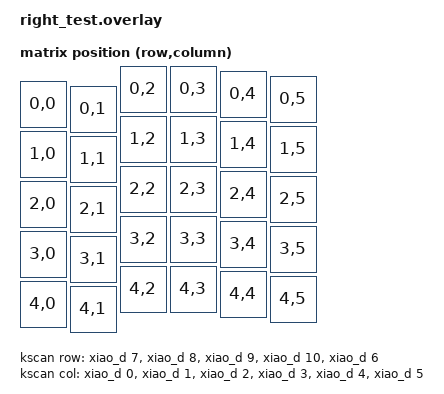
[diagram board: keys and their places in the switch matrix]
// This file was generated from a template. Edit it to match your keyboard.
// See https://zmk.dev/docs/development/hardware-integration/new-shield for more
// instructions.

#include <dt-bindings/zmk/matrix_transform.h>

#include "right_test-layouts.dtsi"

/ {
    chosen {
        zmk,physical-layout = &physical_layout0;
    };

    kscan: kscan {
        // If the hardware does not use a switch matrix, change this to the
        // appropriate driver and update the properties below to match.
        // See https://zmk.dev/docs/config/kscan for supported key scan drivers.
        compatible = "zmk,kscan-gpio-matrix";
        // Set this to "col2row" or "row2col" to match the hardware. If using
        // "row2col", change the col-gpios to (GPIO_ACTIVE_HIGH | GPIO_PULL_DOWN)
        // and the row-gpios to GPIO_ACTIVE_HIGH.
        diode-direction = "col2row";
        wakeup-source;

        // Replace these comments with the GPIO pins in the matrix.
        // See https://zmk.dev/docs/development/hardware-integration/new-shield#shield-overlays
        col-gpios
            = <&xiao_d 0 GPIO_ACTIVE_HIGH>
            , <&xiao_d 1 GPIO_ACTIVE_HIGH>
            , <&xiao_d 2 GPIO_ACTIVE_HIGH>
            , <&xiao_d 3 GPIO_ACTIVE_HIGH>
            , <&xiao_d 4 GPIO_ACTIVE_HIGH>
            , <&xiao_d 5 GPIO_ACTIVE_HIGH>
            ;

        row-gpios
            = <&xiao_d 7 (GPIO_ACTIVE_HIGH | GPIO_PULL_DOWN)>
            , <&xiao_d 8 (GPIO_ACTIVE_HIGH | GPIO_PULL_DOWN)>
            , <&xiao_d 9 (GPIO_ACTIVE_HIGH | GPIO_PULL_DOWN)>
            , <&xiao_d 10 (GPIO_ACTIVE_HIGH | GPIO_PULL_DOWN)>
            , <&xiao_d 6 (GPIO_ACTIVE_HIGH | GPIO_PULL_DOWN)>
            ;
    };

    default_transform: default_transform {
        // See https://zmk.dev/docs/development/hardware-integration/new-shield#matrix-transform
        // for how to configure this
        compatible = "zmk,matrix-transform";
        columns = <6>;
        rows = <5>;

        map = <
            RC(0, 0) RC(0, 1) RC(0, 2) RC(0, 3) RC(0, 4) RC(0, 5)
            RC(1, 0) RC(1, 1) RC(1, 2) RC(1, 3) RC(1, 4) RC(1, 5)
            RC(2, 0) RC(2, 1) RC(2, 2) RC(2, 3) RC(2, 4) RC(2, 5)
            RC(3, 0) RC(3, 1) RC(3, 2) RC(3, 3) RC(3, 4) RC(3, 5)
            RC(4, 0) RC(4, 1) RC(4, 2) RC(4, 3) RC(4, 4) RC(4, 5)

        >;
    };
    physical_layout0: physical_layout_0 { // First physical layout, use different naming for other layouts
        compatible = "zmk,physical-layout";
        display-name = "Default Layout";
        kscan = <&kscan>; // Label of the kscan node, optional if all layouts use the same
        transform = <&default_transform>; // Label of the matrix transform for this layout

        // Key positions below mirror the 6 (inner/index/middle/ring/pinky/outer)
        // x 5 (num/top/home/bottom/mod) matrix from ergogen.yaml, offset per
        // column to reflect each column's `stagger` value. Order matches the
        // RC() order in default_transform / the keymap bindings.
        //                          w    h    x    y    rot   rx   ry
        keys
            = <&key_physical_attrs 100 100    0   30     0     0     0>  // num  - inner
            , <&key_physical_attrs 100 100  100   40     0     0     0>  // num  - index
            , <&key_physical_attrs 100 100  200    0     0     0     0>  // num  - middle
            , <&key_physical_attrs 100 100  300    0     0     0     0>  // num  - ring
            , <&key_physical_attrs 100 100  400   10     0     0     0>  // num  - pinky
            , <&key_physical_attrs 100 100  500   20     0     0     0>  // num  - outer

            , <&key_physical_attrs 100 100    0  130     0     0     0>  // top  - inner
            , <&key_physical_attrs 100 100  100  140     0     0     0>  // top  - index
            , <&key_physical_attrs 100 100  200  100     0     0     0>  // top  - middle
            , <&key_physical_attrs 100 100  300  100     0     0     0>  // top  - ring
            , <&key_physical_attrs 100 100  400  110     0     0     0>  // top  - pinky
            , <&key_physical_attrs 100 100  500  120     0     0     0>  // top  - outer

            , <&key_physical_attrs 100 100    0  230     0     0     0>  // home - inner
            , <&key_physical_attrs 100 100  100  240     0     0     0>  // home - index
            , <&key_physical_attrs 100 100  200  200     0     0     0>  // home - middle
            , <&key_physical_attrs 100 100  300  200     0     0     0>  // home - ring
            , <&key_physical_attrs 100 100  400  210     0     0     0>  // home - pinky
            , <&key_physical_attrs 100 100  500  220     0     0     0>  // home - outer

            , <&key_physical_attrs 100 100    0  330     0     0     0>  // bottom - inner
            , <&key_physical_attrs 100 100  100  340     0     0     0>  // bottom - index
            , <&key_physical_attrs 100 100  200  300     0     0     0>  // bottom - middle
            , <&key_physical_attrs 100 100  300  300     0     0     0>  // bottom - ring
            , <&key_physical_attrs 100 100  400  310     0     0     0>  // bottom - pinky
            , <&key_physical_attrs 100 100  500  320     0     0     0>  // bottom - outer

            , <&key_physical_attrs 100 100    0  430     0     0     0>  // mod - inner
            , <&key_physical_attrs 100 100  100  440     0     0     0>  // mod - index
            , <&key_physical_attrs 100 100  200  400     0     0     0>  // mod - middle
            , <&key_physical_attrs 100 100  300  400     0     0     0>  // mod - ring
            , <&key_physical_attrs 100 100  400  410     0     0     0>  // mod - pinky
            , <&key_physical_attrs 100 100  500  420     0     0     0>  // mod - outer
            ;
    };
};
